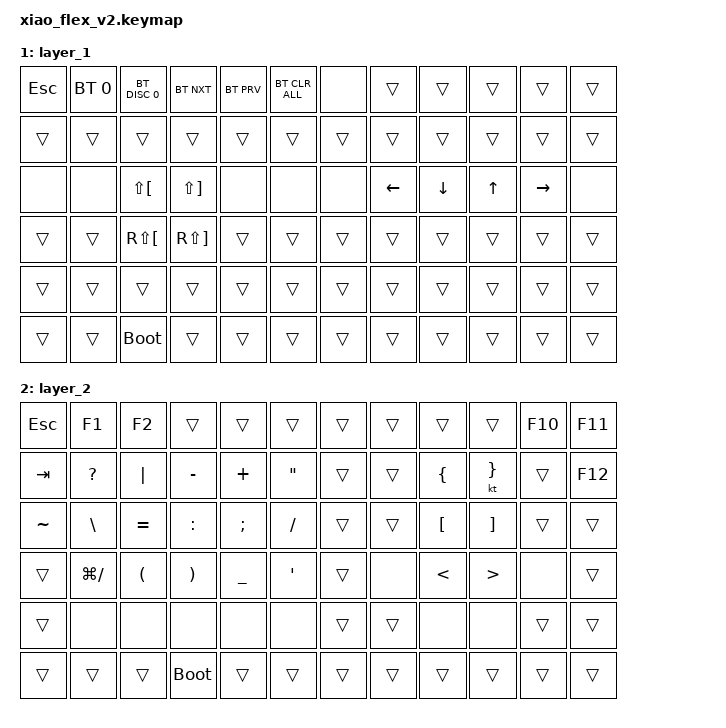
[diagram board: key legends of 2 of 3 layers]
/*
 * Copyright (c) 2020 The ZMK Contributors
 *
 * SPDX-License-Identifier: MIT
 */

#include <behaviors.dtsi>
#include <dt-bindings/zmk/bt.h>
#include <dt-bindings/zmk/keys.h>
#include <dt-bindings/zmk/keys.h>

/ {
    keymap {
        compatible = "zmk,keymap";

        default_layer {
            bindings = <
&kp ESC         &kp NUMBER_1  &kp NUMBER_2  &kp NUMBER_3  &kp NUMBER_4  &kp N5            &kp NUMBER_6     &kp N7         &kp N8     &kp N9         &kp N0     &none
&kp TAB         &kp Q         &kp W         &kp F         &kp P         &kp B             &kp J            &kp L          &kp U      &kp Y          &kp LC(B)  &kp CAPS
&kp GRAVE       &kp A         &kp R         &kp S         &kp T         &kp G             &kp M            &kp N          &kp E      &kp I          &kp O      &kp RIGHT_ALT
&kp LCTRL       &kp Z         &kp X         &kp C         &kp D         &kp V             &kp K            &kp H          &kp COMMA  &kp PERIOD     &kp ENTER  &kp RCTRL
&kp LEFT_SHIFT  &kp SPACE     &kp ENTER     &kp LEFT_WIN  &mo 1         &kp LEFT_SHIFT    &kp RIGHT_SHIFT  &kp BACKSPACE  &kp LC(B)  &kp RIGHT_WIN  &mo 2      &kp RSHIFT
&none           &none         &none         &none         &none         &none             &none            &none          &none      &none          &none      &none
&none           &none         &none         &none         &none         &none             &none            &none          &none      &none          &none      &none
            >;
        };

        layer_1 {
            bindings = <
&kp ESC  &bt BT_SEL 0  &bt BT_DISC 0         &bt BT_NXT             &bt BT_PRV  &bt BT_CLR_ALL    &none   &trans          &trans    &trans  &trans     &trans
&trans   &trans        &trans                &trans                 &trans      &trans            &trans  &trans          &trans    &trans  &trans     &trans
&none    &none         &kp LS(LEFT_BRACKET)  &kp LS(RIGHT_BRACKET)  &none       &none             &none   &kp LEFT_ARROW  &kp DOWN  &kp UP  &kp RIGHT  &none
&trans   &trans        &kp RS(LEFT_BRACKET)  &kp RS(RIGHT_BRACKET)  &trans      &trans            &trans  &trans          &trans    &trans  &trans     &trans
&trans   &trans        &trans                &trans                 &trans      &trans            &trans  &trans          &trans    &trans  &trans     &trans
&trans   &trans        &bootloader           &trans                 &trans      &trans            &trans  &trans          &trans    &trans  &trans     &trans
            >;
        };

        layer_2 {
            bindings = <
&kp ESC    &kp F1         &kp F2                &trans                 &trans          &trans               &trans  &trans  &trans            &trans             &kp F10  &kp F11
&kp TAB    &kp QUESTION   &kp PIPE              &kp MINUS              &kp PLUS        &kp DOUBLE_QUOTES    &trans  &trans  &kp LEFT_BRACE    &kt RIGHT_BRACE    &trans   &kp F12
&kp TILDE  &kp BACKSLASH  &kp EQUAL             &kp COLON              &kp SEMICOLON   &kp SLASH            &trans  &trans  &kp LEFT_BRACKET  &kp RIGHT_BRACKET  &trans   &trans
&trans     &kp LG(SLASH)  &kp LEFT_PARENTHESIS  &kp RIGHT_PARENTHESIS  &kp UNDERSCORE  &kp SINGLE_QUOTE     &trans  &none   &kp LESS_THAN     &kp GREATER_THAN   &none    &trans
&trans     &none          &none                 &none                  &none           &none                &trans  &trans  &none             &none              &trans   &trans
&trans     &trans         &trans                &bootloader            &trans          &trans               &trans  &trans  &trans            &trans             &trans   &trans
            >;
        };
    };
};
